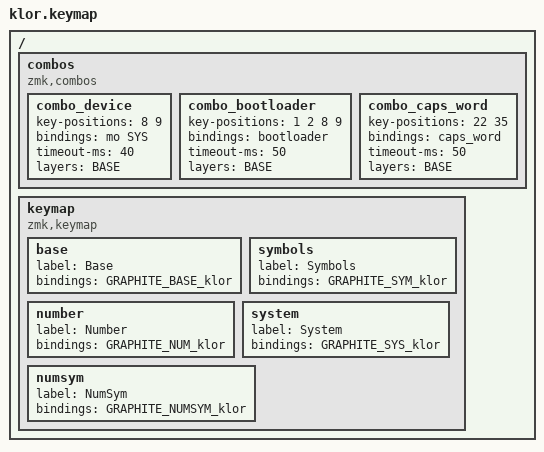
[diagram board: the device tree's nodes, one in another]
/*
 * KLOR (nice!nano) — Graphite layout
 *
 * klor shares the fleet-wide Graphite system (config/graphite.dtsi: BASE/SYM/
 * NUM/SYS/NUMSYM). Its physical shape equals Corne_36 (5/6/6 per side, 2-key
 * outer pinky column on rows 1-2) PLUS, per side, one extra outer thumb and one
 * encoder push — both currently &none.
 *
 * Transform fill order (config/boards/shields/klor/klor.dtsi), 44 positions:
 *   row0 (10):  RC0,1..0,5            | RC0,6..0,10
 *   row1 (12):  RC1,0..1,5            | RC1,6..1,11
 *   row2 (14):  RC2,0..2,5  RC3,5 RC3,6  RC2,6..2,11   (RC3,5/RC3,6 = encoders, &none)
 *   thumbs (8): RC3,1 RC3,2 RC3,3 RC3,4 | RC3,7 RC3,8 RC3,9 RC3,10
 *               (outermost thumb each side = extra, &none)
 */

#include <behaviors.dtsi>
#include <dt-bindings/zmk/keys.h>
#include <dt-bindings/zmk/bt.h>
#include <dt-bindings/zmk/outputs.h>
#include <dt-bindings/zmk/rgb.h>

#include "graphite.dtsi"

/* ===========================================================================
 * klor-sized layer macros — Graphite _36 content placed on klor's transform.
 * Each macro is 44 bindings in the fill order above. &none marks the 2 encoder
 * positions (mid-row2) and the 2 extra outer thumbs.
 * =========================================================================== */

// row0: corne_36 row0 inner-10 (drops outer ESC + &none corners)
// row1: full 12 (outer pinky present)
// row2: 6 left | &none &none (encoders) | 6 right
// thumbs: &none CTRL sym_ht SPC | RET BSPC RALT &none
#define GRAPHITE_BASE_klor \
    &kp B    &kp L    &kp D    &kp W    &kp Z                          &kp SEMI &kp F    &kp O    &kp U    &kp J    \
    &kp TAB  &kp N    &kp R    &kp T    &kp S    &kp G                 &kp Y    &kp H    &kp A    &kp E    &kp I    &none \
    &kp LSHFT &kp Q   &kp X    &kp M    &kp C    &kp V  &none &none    &kp K    &kp P    &kp COMMA &kp DOT &slash_morph &kp RSHFT \
                      &none    &kp LCTRL &sym_ht SYM SYM &kp SPC       &kp RET  &kp BSPC &kp RALT &none

#define GRAPHITE_SYM_klor \
    &kp AMPS &kp LPAR &kp RPAR &kp EXCL &kp QMARK                      &kp COLON &kp EQUAL &plus_pipe_morph &kp MINUS &kp GRAVE \
    &mo NUM  &kp CARET &kp LBKT &mo_ht NUM RBKT &lgui_ht LGUI DOLLAR &kp PRCNT  &kp PG_UP &kp LEFT &kp DOWN &kp UP   &kp RIGHT &trans \
    &trans   &kp ASTRK &lgui_ht LSHFT LBRC &kp RBRC &kp AT &kp HASH &none &none &kp PG_DN &kp HOME &kp END  &kp SQT  &kp BSLH &trans \
                      &none    &kp LCTRL &trans   &trans                &trans   &kp DEL  &trans   &none

#define GRAPHITE_NUM_klor \
    &kp HOME &kp PG_UP &kp PG_DN &kp END &trans                        &trans   &kp N7   &kp N8   &kp N9   &trans   \
    &trans   &kp LEFT &kp UP   &kp DOWN &kp RIGHT &trans               &trans   &kp N4   &kp N5   &kp N6   &trans   &trans \
    &kp TAB  &trans   &trans   &trans   &trans   &trans  &none &none   &trans   &kp N1   &kp N2   &kp N3   &kp N0   &trans \
                      &none    &trans   &trans   &trans                &kp RET  &kp RALT &trans   &none

#define GRAPHITE_SYS_klor \
    &out OUT_TOG &trans &trans &trans  &trans                          &trans   &kp C_PP &kp C_NEXT &trans &trans  \
    &kp PSCRN &bt BT_SEL 0 &bt BT_SEL 1 &bt BT_SEL 2 &bt BT_SEL 3 &trans       &kp C_VOL_DN &kp C_VOL_UP &kp C_BRI_DN &kp C_BRI_UP &trans &trans \
    &trans   &trans   &trans   &trans   &trans   &trans  &none &none   &trans   &trans   &bt BT_CLR_ALL &trans &trans &trans \
                      &none    &trans   &trans   &trans                &trans   &trans   &trans   &none

#define GRAPHITE_NUMSYM_klor \
    &trans   &trans   &trans   &trans   &trans                         &trans   &kp N7   &kp N8   &kp N9   &trans   \
    &trans   &trans   &trans   &trans   &trans   &trans                &trans   &kp N4   &kp N5   &kp N6   &trans   &trans \
    &trans   &trans   &trans   &trans   &trans   &trans  &none &none   &trans   &kp N1   &kp N2   &kp N3   &kp N0   &trans \
                      &none    &trans   &trans   &kp RET               &trans   &trans   &trans   &none

/ {
    combos {
        compatible = "zmk,combos";

        // Mirrors corne's combo set, adapted to klor's transform positions.
        // klor row0 fill: pos 0-4 = B L D W Z (left), pos 5-9 = SEMI F O U J (right).
        //   -> L=1, D=2, U=8, J=9.

        // U+J: hold for SYS layer (where &out OUT_TOG lives).
        combo_device {
            key-positions = <8 9>;
            bindings = <&mo SYS>;
            timeout-ms = <40>;
            layers = <BASE>;
        };

        // L+D+U+J: bootloader.
        combo_bootloader {
            key-positions = <1 2 8 9>;
            bindings = <&bootloader>;
            timeout-ms = <50>;
            layers = <BASE>;
        };

        // both shifts (outer pinky row2: pos 22 = LSHFT left edge, 35 = RSHFT right edge): caps word.
        combo_caps_word {
            key-positions = <22 35>;
            bindings = <&caps_word>;
            timeout-ms = <50>;
            layers = <BASE>;
        };
    };

    keymap {
        compatible = "zmk,keymap";

        base {
            label = "Base";
            bindings = < GRAPHITE_BASE_klor >;
        };

        symbols {
            label = "Symbols";
            bindings = < GRAPHITE_SYM_klor >;
        };

        number {
            label = "Number";
            bindings = < GRAPHITE_NUM_klor >;
        };

        system {
            label = "System";
            bindings = < GRAPHITE_SYS_klor >;
        };

        numsym {
            label = "NumSym";
            bindings = < GRAPHITE_NUMSYM_klor >;
        };
    };
};
